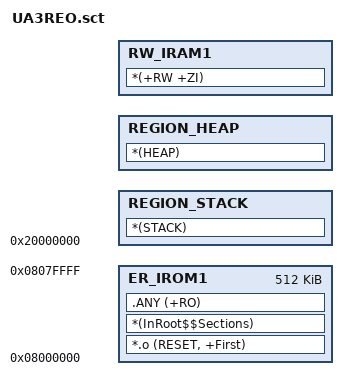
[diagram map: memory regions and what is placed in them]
; This scatter file places stack before .bss region, so on stack overflow
; we get HardFault exception immediately
 
LR_IROM1 0x8000000 0x80000  {    ; load region size_region
  ER_IROM1 0x8000000 0x80000  {  ; load address = execution address
    *.o (RESET, +First)
    *(InRoot$$Sections)
    .ANY (+RO)
  }
 
  ; Stack region growing down
  REGION_STACK 0x20000000 {
    *(STACK)
  }
 
  ; We have to define heap region, even if we don't actually use heap
  REGION_HEAP ImageLimit(REGION_STACK) {
    *(HEAP)
  }
 
  ; this will place .bss region above the stack and heap and allocate RAM that is left for it
  RW_IRAM1 ImageLimit(REGION_HEAP) (0x20000 - ImageLength(REGION_STACK) - ImageLength(REGION_HEAP))  {  
    *(+RW +ZI)
  }
}
